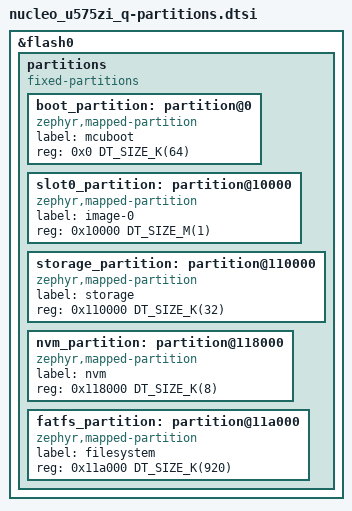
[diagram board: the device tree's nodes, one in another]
/* Partition layout for nucleo_u575zi_q: the flash memory map shared by the
 * bootloader and every application image. Generated by
 * tools/partition_layout.py; do not edit by hand -- re-run
 * `python3 tools/partition_layout.py --fix nucleo_u575zi_q` after changing
 * the upstream board geometry or tools/boards.toml.
 *
 * Board-specific overlay glue (delete-nodes, device enablement,
 * aliases/chosen) lives in dts/st/nucleo_u575zi_q.dtsi, which includes
 * this file.
 */

&flash0 {
	partitions {
		compatible = "fixed-partitions";
		#address-cells = <1>;
		#size-cells = <1>;

		boot_partition: partition@0 {
			compatible = "zephyr,mapped-partition";
			label = "mcuboot";
			reg = <0x0 DT_SIZE_K(64)>;
		};

		slot0_partition: partition@10000 {
			compatible = "zephyr,mapped-partition";
			label = "image-0";
			reg = <0x10000 DT_SIZE_M(1)>;
		};

		storage_partition: partition@110000 {
			compatible = "zephyr,mapped-partition";
			label = "storage";
			reg = <0x110000 DT_SIZE_K(32)>;
		};

		nvm_partition: partition@118000 {
			compatible = "zephyr,mapped-partition";
			label = "nvm";
			reg = <0x118000 DT_SIZE_K(8)>;
		};

		fatfs_partition: partition@11a000 {
			compatible = "zephyr,mapped-partition";
			label = "filesystem";
			reg = <0x11a000 DT_SIZE_K(920)>;
		};
	};
};
